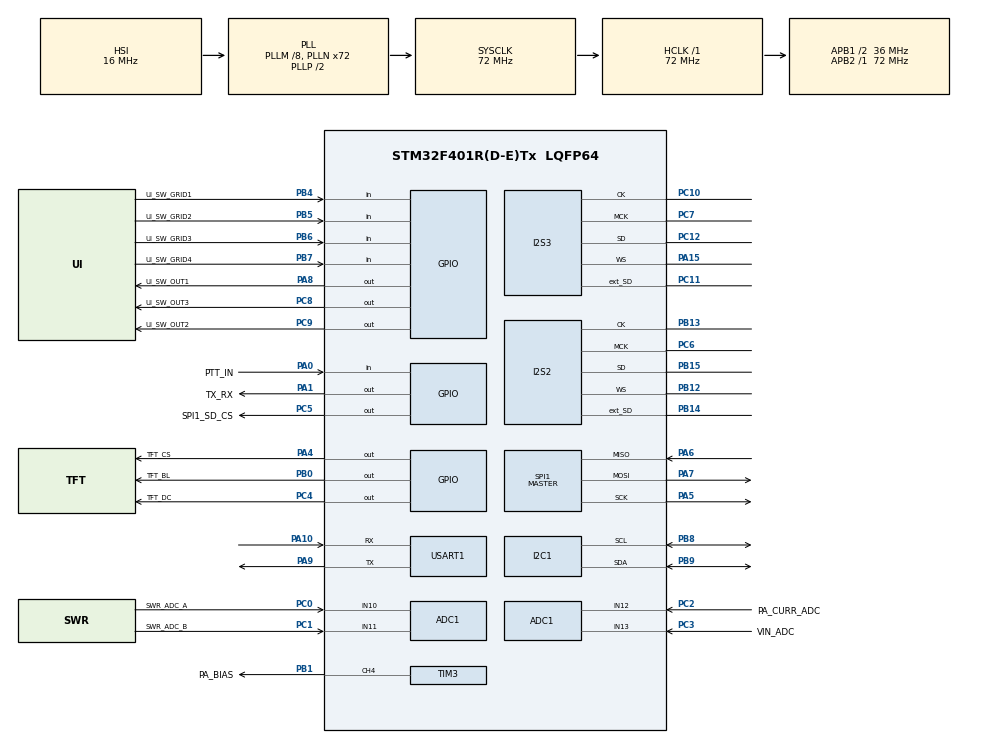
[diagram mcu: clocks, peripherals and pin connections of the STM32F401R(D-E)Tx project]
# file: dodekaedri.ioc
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ADC1.Channel-0\#ChannelRegularConversion=ADC_CHANNEL_13
ADC1.NbrOfConversionFlag=1
ADC1.Rank-0\#ChannelRegularConversion=1
ADC1.SamplingTime-0\#ChannelRegularConversion=ADC_SAMPLETIME_3CYCLES
ADC1.master=1
FREERTOS.Mutexes01=i2c_mutex
FREERTOS.Tasks01=defaultTask,0,128,StartDefaultTask,Default,NULL,Dynamic,NULL,NULL;ui_task,0,128,start_ui_task,As external,NULL,Dynamic,NULL,NULL;synth_task,0,128,start_synth_task,As external,NULL,Dynamic,NULL,NULL;dsp_task,1,128,start_dsp_task,As external,NULL,Dynamic,NULL,NULL
I2S2.AudioFreq=AudioFreqCustomValue
I2S2.AudioFreqCustom=50000
I2S2.ErrorAudioFreq=0.0 %
I2S2.FullDuplexMode=I2S_FULLDUPLEXMODE_ENABLE
I2S2.RealAudioFreq=50.0 KHz
I2S3.AudioFreq=AudioFreqCustomValue
I2S3.AudioFreqCustom=50000
I2S3.ErrorAudioFreq=0.0 %
I2S3.FullDuplexMode=I2S_FULLDUPLEXMODE_ENABLE
I2S3.RealAudioFreq=50.0 KHz
Mcu.Family=STM32F4
Mcu.Name=STM32F401R(D-E)Tx
Mcu.Package=LQFP64
NVIC.PriorityGroup=NVIC_PRIORITYGROUP_4
NVIC.SPI2_IRQn=true\:5\:0\:false\:false\:true\:true
PA0-WKUP.GPIO_Label=PTT_IN
PA0-WKUP.Signal=GPIO_Input
PA1.GPIO_Label=TX_RX
PA1.Signal=GPIO_Output
PA10.Mode=Asynchronous
PA10.Signal=USART1_RX
PA13.Signal=SYS_JTMS-SWDIO
PA14.Signal=SYS_JTCK-SWCLK
PA15.Mode=Full_Duplex_Master
PA15.Signal=I2S3_WS
PA4.GPIO_Label=TFT_CS
PA4.Signal=GPIO_Output
PA5.Mode=Full_Duplex_Master
PA5.Signal=SPI1_SCK
PA6.Mode=Full_Duplex_Master
PA6.Signal=SPI1_MISO
PA7.Mode=Full_Duplex_Master
PA7.Signal=SPI1_MOSI
PA8.GPIO_Label=UI_SW_OUT1
PA8.Signal=GPIO_Output
PA9.Mode=Asynchronous
PA9.Signal=USART1_TX
PB0.GPIO_Label=TFT_BL
PB0.Signal=GPIO_Output
PB1.GPIO_Label=PA_BIAS
PB1.Signal=S_TIM3_CH4
PB12.Mode=Full_Duplex_Master
PB12.Signal=I2S2_WS
PB13.Mode=Full_Duplex_Master
PB13.Signal=I2S2_CK
PB14.Mode=Full_Duplex_Master
PB14.Signal=I2S2_ext_SD
PB15.Mode=Full_Duplex_Master
PB15.Signal=I2S2_SD
PB3.Signal=SYS_JTDO-SWO
PB4.GPIO_Label=UI_SW_GRID1
PB4.Signal=GPIO_Input
PB5.GPIO_Label=UI_SW_GRID2
PB5.Signal=GPIO_Input
PB6.GPIO_Label=UI_SW_GRID3
PB6.Signal=GPIO_Input
PB7.GPIO_Label=UI_SW_GRID4
PB7.Signal=GPIO_Input
PB8.Mode=I2C
PB8.Signal=I2C1_SCL
PB9.Mode=I2C
PB9.Signal=I2C1_SDA
PC0.GPIO_Label=SWR_ADC_A
PC0.Signal=ADCx_IN10
PC1.GPIO_Label=SWR_ADC_B
PC1.Signal=ADCx_IN11
PC10.Mode=Full_Duplex_Master
PC10.Signal=I2S3_CK
PC11.Mode=Full_Duplex_Master
PC11.Signal=I2S3_ext_SD
PC12.Mode=Full_Duplex_Master
PC12.Signal=I2S3_SD
PC2.GPIO_Label=PA_CURR_ADC
PC2.Signal=ADCx_IN12
PC3.GPIO_Label=VIN_ADC
PC3.Signal=ADCx_IN13
PC4.GPIO_Label=TFT_DC
PC4.Signal=GPIO_Output
PC5.GPIO_Label=SPI1_SD_CS
PC5.Signal=GPIO_Output
PC6.Mode=Master_Clock_Activated
PC6.Signal=I2S2_MCK
PC7.Mode=Master_Clock_Activated
PC7.Signal=I2S3_MCK
PC8.GPIO_Label=UI_SW_OUT3
PC8.Signal=GPIO_Output
PC9.GPIO_Label=UI_SW_OUT2
PC9.Signal=GPIO_Output
PH0\ -\ OSC_IN.Mode=HSE-External-Clock-Source
PH0\ -\ OSC_IN.Signal=RCC_OSC_IN
PH1\ -\ OSC_OUT.Mode=HSE-External-Clock-Source
PH1\ -\ OSC_OUT.Signal=RCC_OSC_OUT
ProjectManager.HeapSize=0x200
ProjectManager.StackSize=0x400
ProjectManager.TargetToolchain=SW4STM32
RCC.48MHZClocksFreq_Value=48000000
RCC.AHBFreq_Value=72000000
RCC.APB1CLKDivider=RCC_HCLK_DIV2
RCC.APB1Freq_Value=36000000
RCC.APB1TimFreq_Value=72000000
RCC.APB2Freq_Value=72000000
RCC.APB2TimFreq_Value=72000000
RCC.CortexFreq_Value=72000000
RCC.HCLKFreq_Value=72000000
RCC.HSE_VALUE=25000000
RCC.HSI_VALUE=16000000
RCC.LSE_VALUE=32768
RCC.PLLM=8
RCC.PLLN=72
RCC.PLLQ=3
RCC.SYSCLKFreq_VALUE=72000000
RCC.SYSCLKSource=RCC_SYSCLKSOURCE_PLLCLK
RCC.VCOOutputFreq_Value=144000000
SH.ADCx_IN10.0=ADC1_IN10,IN10
SH.ADCx_IN11.0=ADC1_IN11,IN11
SH.ADCx_IN12.0=ADC1_IN12,IN12
SH.ADCx_IN13.0=ADC1_IN13,IN13
SH.S_TIM3_CH4.0=TIM3_CH4,PWM Generation4 CH4
SPI1.Mode=SPI_MODE_MASTER
TIM3.Channel-PWM\ Generation4\ CH4=TIM_CHANNEL_4
VP_FREERTOS_VS_ENABLE.Mode=Enabled
board=dodekaedri

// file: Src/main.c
/**
  ******************************************************************************
  * File Name          : main.c
  * Description        : Main program body
  ******************************************************************************
  *
  * Copyright (c) 2017 STMicroelectronics International N.V.
  * All rights reserved.
  *
  * Redistribution and use in source and binary forms, with or without
  * modification, are permitted, provided that the following conditions are met:
  *
  * 1. Redistribution of source code must retain the above copyright notice,
  *    this list of conditions and the following disclaimer.
  * 2. Redistributions in binary form must reproduce the above copyright notice,
  *    this list of conditions and the following disclaimer in the documentation
  *    and/or other materials provided with the distribution.
  * 3. Neither the name of STMicroelectronics nor the names of other
  *    contributors to this software may be used to endorse or promote products
  *    derived from this software without specific written permission.
  * 4. This software, including modifications and/or derivative works of this
  *    software, must execute solely and exclusively on microcontroller or
  *    microprocessor devices manufactured by or for STMicroelectronics.
  * 5. Redistribution and use of this software other than as permitted under
  *    this license is void and will automatically terminate your rights under
  *    this license.
  *
  * THIS SOFTWARE IS PROVIDED BY STMICROELECTRONICS AND CONTRIBUTORS "AS IS"
  * AND ANY EXPRESS, IMPLIED OR STATUTORY WARRANTIES, INCLUDING, BUT NOT
  * LIMITED TO, THE IMPLIED WARRANTIES OF MERCHANTABILITY, FITNESS FOR A
  * PARTICULAR PURPOSE AND NON-INFRINGEMENT OF THIRD PARTY INTELLECTUAL PROPERTY
  * RIGHTS ARE DISCLAIMED TO THE FULLEST EXTENT PERMITTED BY LAW. IN NO EVENT
  * SHALL STMICROELECTRONICS OR CONTRIBUTORS BE LIABLE FOR ANY DIRECT, INDIRECT,
  * INCIDENTAL, SPECIAL, EXEMPLARY, OR CONSEQUENTIAL DAMAGES (INCLUDING, BUT NOT
  * LIMITED TO, PROCUREMENT OF SUBSTITUTE GOODS OR SERVICES; LOSS OF USE, DATA,
  * OR PROFITS; OR BUSINESS INTERRUPTION) HOWEVER CAUSED AND ON ANY THEORY OF
  * LIABILITY, WHETHER IN CONTRACT, STRICT LIABILITY, OR TORT (INCLUDING
  * NEGLIGENCE OR OTHERWISE) ARISING IN ANY WAY OUT OF THE USE OF THIS SOFTWARE,
  * EVEN IF ADVISED OF THE POSSIBILITY OF SUCH DAMAGE.
  *
  ******************************************************************************
  */
#include "main.h"
#include "stm32f4xx_hal.h"
#include "cmsis_os.h"

ADC_HandleTypeDef hadc1;

I2C_HandleTypeDef hi2c1;

I2S_HandleTypeDef hi2s2;
I2S_HandleTypeDef hi2s3;

SPI_HandleTypeDef hspi1;

TIM_HandleTypeDef htim3;

UART_HandleTypeDef huart1;

osThreadId defaultTaskHandle;
osThreadId ui_taskHandle;
osThreadId synth_taskHandle;
osThreadId dsp_taskHandle;
osMutexId i2c_mutexHandle;

/* USER CODE BEGIN PV */
/* Private variables ---------------------------------------------------------*/

/* USER CODE END PV */

void SystemClock_Config(void);
void Error_Handler(void);
static void MX_GPIO_Init(void);
static void MX_ADC1_Init(void);
static void MX_SPI1_Init(void);
static void MX_TIM3_Init(void);
static void MX_I2S2_Init(void);
static void MX_I2S3_Init(void);
static void MX_I2C1_Init(void);
static void MX_USART1_UART_Init(void);
void StartDefaultTask(void const * argument);
extern void start_ui_task(void const * argument);
extern void start_synth_task(void const * argument);
extern void start_dsp_task(void const * argument);

void HAL_TIM_MspPostInit(TIM_HandleTypeDef *htim);

/* USER CODE BEGIN PFP */
/* Private function prototypes -----------------------------------------------*/

/* USER CODE END PFP */

int main(void)
{

  /* MCU Configuration----------------------------------------------------------*/

  /* Reset of all peripherals, Initializes the Flash interface and the Systick. */
  HAL_Init();

  /* Configure the system clock */
  SystemClock_Config();

  /* Initialize all configured peripherals */
  MX_GPIO_Init();
  MX_ADC1_Init();
  MX_SPI1_Init();
  MX_TIM3_Init();
  MX_I2S2_Init();
  MX_I2S3_Init();
  MX_I2C1_Init();
  MX_USART1_UART_Init();

  /* USER CODE BEGIN 2 */
  HAL_UART_Transmit(&huart1, "MCU peripherals initialized. Starting kernel\r\n", 47, 100);

  /* USER CODE END 2 */

  /* Create the mutex(es) */
  /* definition and creation of i2c_mutex */
  osMutexDef(i2c_mutex);
  i2c_mutexHandle = osMutexCreate(osMutex(i2c_mutex));

  /* Create the thread(s) */
  /* definition and creation of defaultTask */
  osThreadDef(defaultTask, StartDefaultTask, osPriorityNormal, 0, 128);
  defaultTaskHandle = osThreadCreate(osThread(defaultTask), NULL);

  /* definition and creation of ui_task */
  osThreadDef(ui_task, start_ui_task, osPriorityNormal, 0, 128);
  ui_taskHandle = osThreadCreate(osThread(ui_task), NULL);

  /* definition and creation of synth_task */
  osThreadDef(synth_task, start_synth_task, osPriorityNormal, 0, 128);
  synth_taskHandle = osThreadCreate(osThread(synth_task), NULL);

  /* definition and creation of dsp_task */
  osThreadDef(dsp_task, start_dsp_task, osPriorityAboveNormal, 0, 128);
  dsp_taskHandle = osThreadCreate(osThread(dsp_task), NULL);

  /* Start scheduler */
  osKernelStart();

  /* We should never get here as control is now taken by the scheduler */

  /* Infinite loop */
  while (1)
  {

  }

}

/** System Clock Configuration
*/
void SystemClock_Config(void)
{

  RCC_OscInitTypeDef RCC_OscInitStruct;
  RCC_ClkInitTypeDef RCC_ClkInitStruct;
  RCC_PeriphCLKInitTypeDef PeriphClkInitStruct;

    /**Configure the main internal regulator output voltage
    */
  __HAL_RCC_PWR_CLK_ENABLE();

  __HAL_PWR_VOLTAGESCALING_CONFIG(PWR_REGULATOR_VOLTAGE_SCALE2);

    /**Initializes the CPU, AHB and APB busses clocks
    */
  RCC_OscInitStruct.OscillatorType = RCC_OSCILLATORTYPE_HSI;
  RCC_OscInitStruct.HSIState = RCC_HSI_ON;
  RCC_OscInitStruct.HSICalibrationValue = 16;
  RCC_OscInitStruct.PLL.PLLState = RCC_PLL_ON;
  RCC_OscInitStruct.PLL.PLLSource = RCC_PLLSOURCE_HSI;
  RCC_OscInitStruct.PLL.PLLM = 8;
  RCC_OscInitStruct.PLL.PLLN = 72;
  RCC_OscInitStruct.PLL.PLLP = RCC_PLLP_DIV2;
  RCC_OscInitStruct.PLL.PLLQ = 3;
  if (HAL_RCC_OscConfig(&RCC_OscInitStruct) != HAL_OK)
  {
    Error_Handler();
  }

    /**Initializes the CPU, AHB and APB busses clocks
    */
  RCC_ClkInitStruct.ClockType = RCC_CLOCKTYPE_HCLK|RCC_CLOCKTYPE_SYSCLK
                              |RCC_CLOCKTYPE_PCLK1|RCC_CLOCKTYPE_PCLK2;
  RCC_ClkInitStruct.SYSCLKSource = RCC_SYSCLKSOURCE_PLLCLK;
  RCC_ClkInitStruct.AHBCLKDivider = RCC_SYSCLK_DIV1;
  RCC_ClkInitStruct.APB1CLKDivider = RCC_HCLK_DIV2;
  RCC_ClkInitStruct.APB2CLKDivider = RCC_HCLK_DIV1;

  if (HAL_RCC_ClockConfig(&RCC_ClkInitStruct, FLASH_LATENCY_2) != HAL_OK)
  {
    Error_Handler();
  }

  PeriphClkInitStruct.PeriphClockSelection = RCC_PERIPHCLK_I2S;
  PeriphClkInitStruct.PLLI2S.PLLI2SN = 192;
  PeriphClkInitStruct.PLLI2S.PLLI2SR = 2;
  if (HAL_RCCEx_PeriphCLKConfig(&PeriphClkInitStruct) != HAL_OK)
  {
    Error_Handler();
  }

    /**Configure the Systick interrupt time
    */
  HAL_SYSTICK_Config(HAL_RCC_GetHCLKFreq()/1000);

    /**Configure the Systick
    */
  HAL_SYSTICK_CLKSourceConfig(SYSTICK_CLKSOURCE_HCLK);

  /* SysTick_IRQn interrupt configuration */
  HAL_NVIC_SetPriority(SysTick_IRQn, 15, 0);
}

/* ADC1 init function */
static void MX_ADC1_Init(void)
{

  ADC_ChannelConfTypeDef sConfig;

    /**Configure the global features of the ADC (Clock, Resolution, Data Alignment and number of conversion)
    */
  hadc1.Instance = ADC1;
  hadc1.Init.ClockPrescaler = ADC_CLOCK_SYNC_PCLK_DIV2;
  hadc1.Init.Resolution = ADC_RESOLUTION_12B;
  hadc1.Init.ScanConvMode = DISABLE;
  hadc1.Init.ContinuousConvMode = DISABLE;
  hadc1.Init.DiscontinuousConvMode = DISABLE;
  hadc1.Init.ExternalTrigConvEdge = ADC_EXTERNALTRIGCONVEDGE_NONE;
  hadc1.Init.ExternalTrigConv = ADC_SOFTWARE_START;
  hadc1.Init.DataAlign = ADC_DATAALIGN_RIGHT;
  hadc1.Init.NbrOfConversion = 1;
  hadc1.Init.DMAContinuousRequests = DISABLE;
  hadc1.Init.EOCSelection = ADC_EOC_SINGLE_CONV;
  if (HAL_ADC_Init(&hadc1) != HAL_OK)
  {
    Error_Handler();
  }

    /**Configure for the selected ADC regular channel its corresponding rank in the sequencer and its sample time.
    */
  sConfig.Channel = ADC_CHANNEL_13;
  sConfig.Rank = 1;
  sConfig.SamplingTime = ADC_SAMPLETIME_3CYCLES;
  if (HAL_ADC_ConfigChannel(&hadc1, &sConfig) != HAL_OK)
  {
    Error_Handler();
  }

}

/* I2C1 init function */
static void MX_I2C1_Init(void)
{

  hi2c1.Instance = I2C1;
  hi2c1.Init.ClockSpeed = 100000;
  hi2c1.Init.DutyCycle = I2C_DUTYCYCLE_2;
  hi2c1.Init.OwnAddress1 = 0;
  hi2c1.Init.AddressingMode = I2C_ADDRESSINGMODE_7BIT;
  hi2c1.Init.DualAddressMode = I2C_DUALADDRESS_DISABLE;
  hi2c1.Init.OwnAddress2 = 0;
  hi2c1.Init.GeneralCallMode = I2C_GENERALCALL_DISABLE;
  hi2c1.Init.NoStretchMode = I2C_NOSTRETCH_DISABLE;
  if (HAL_I2C_Init(&hi2c1) != HAL_OK)
  {
    Error_Handler();
  }

}

/* I2S2 init function */
static void MX_I2S2_Init(void)
{

  hi2s2.Instance = SPI2;
  hi2s2.Init.Mode = I2S_MODE_MASTER_TX;
  hi2s2.Init.Standard = I2S_STANDARD_PHILIPS;
  hi2s2.Init.DataFormat = I2S_DATAFORMAT_16B;
  hi2s2.Init.MCLKOutput = I2S_MCLKOUTPUT_ENABLE;
  hi2s2.Init.AudioFreq = 50000;
  hi2s2.Init.CPOL = I2S_CPOL_LOW;
  hi2s2.Init.ClockSource = I2S_CLOCK_PLL;
  hi2s2.Init.FullDuplexMode = I2S_FULLDUPLEXMODE_ENABLE;
  if (HAL_I2S_Init(&hi2s2) != HAL_OK)
  {
    Error_Handler();
  }

}

/* I2S3 init function */
static void MX_I2S3_Init(void)
{

  hi2s3.Instance = SPI3;
  hi2s3.Init.Mode = I2S_MODE_MASTER_TX;
  hi2s3.Init.Standard = I2S_STANDARD_PHILIPS;
  hi2s3.Init.DataFormat = I2S_DATAFORMAT_16B;
  hi2s3.Init.MCLKOutput = I2S_MCLKOUTPUT_ENABLE;
  hi2s3.Init.AudioFreq = 50000;
  hi2s3.Init.CPOL = I2S_CPOL_LOW;
  hi2s3.Init.ClockSource = I2S_CLOCK_PLL;
  hi2s3.Init.FullDuplexMode = I2S_FULLDUPLEXMODE_ENABLE;
  if (HAL_I2S_Init(&hi2s3) != HAL_OK)
  {
    Error_Handler();
  }

}

/* SPI1 init function */
static void MX_SPI1_Init(void)
{

  hspi1.Instance = SPI1;
  hspi1.Init.Mode = SPI_MODE_MASTER;
  hspi1.Init.Direction = SPI_DIRECTION_2LINES;
  hspi1.Init.DataSize = SPI_DATASIZE_8BIT;
  hspi1.Init.CLKPolarity = SPI_POLARITY_LOW;
  hspi1.Init.CLKPhase = SPI_PHASE_1EDGE;
  hspi1.Init.NSS = SPI_NSS_SOFT;
  hspi1.Init.BaudRatePrescaler = SPI_BAUDRATEPRESCALER_2;
  hspi1.Init.FirstBit = SPI_FIRSTBIT_MSB;
  hspi1.Init.TIMode = SPI_TIMODE_DISABLE;
  hspi1.Init.CRCCalculation = SPI_CRCCALCULATION_DISABLE;
  hspi1.Init.CRCPolynomial = 10;
  if (HAL_SPI_Init(&hspi1) != HAL_OK)
  {
    Error_Handler();
  }

}

/* TIM3 init function */
static void MX_TIM3_Init(void)
{

  TIM_MasterConfigTypeDef sMasterConfig;
  TIM_OC_InitTypeDef sConfigOC;

  htim3.Instance = TIM3;
  htim3.Init.Prescaler = 0;
  htim3.Init.CounterMode = TIM_COUNTERMODE_UP;
  htim3.Init.Period = 0;
  htim3.Init.ClockDivision = TIM_CLOCKDIVISION_DIV1;
  if (HAL_TIM_PWM_Init(&htim3) != HAL_OK)
  {
    Error_Handler();
  }

  sMasterConfig.MasterOutputTrigger = TIM_TRGO_RESET;
  sMasterConfig.MasterSlaveMode = TIM_MASTERSLAVEMODE_DISABLE;
  if (HAL_TIMEx_MasterConfigSynchronization(&htim3, &sMasterConfig) != HAL_OK)
  {
    Error_Handler();
  }

  sConfigOC.OCMode = TIM_OCMODE_PWM1;
  sConfigOC.Pulse = 0;
  sConfigOC.OCPolarity = TIM_OCPOLARITY_HIGH;
  sConfigOC.OCFastMode = TIM_OCFAST_DISABLE;
  if (HAL_TIM_PWM_ConfigChannel(&htim3, &sConfigOC, TIM_CHANNEL_4) != HAL_OK)
  {
    Error_Handler();
  }

  HAL_TIM_MspPostInit(&htim3);

}

/* USART1 init function */
static void MX_USART1_UART_Init(void)
{

  huart1.Instance = USART1;
  huart1.Init.BaudRate = 115200;
  huart1.Init.WordLength = UART_WORDLENGTH_8B;
  huart1.Init.StopBits = UART_STOPBITS_1;
  huart1.Init.Parity = UART_PARITY_NONE;
  huart1.Init.Mode = UART_MODE_TX_RX;
  huart1.Init.HwFlowCtl = UART_HWCONTROL_NONE;
  huart1.Init.OverSampling = UART_OVERSAMPLING_16;
  if (HAL_UART_Init(&huart1) != HAL_OK)
  {
    Error_Handler();
  }

}

/** Configure pins as
        * Analog
        * Input
        * Output
        * EVENT_OUT
        * EXTI
*/
static void MX_GPIO_Init(void)
{

  GPIO_InitTypeDef GPIO_InitStruct;

  /* GPIO Ports Clock Enable */
  __HAL_RCC_GPIOH_CLK_ENABLE();
  __HAL_RCC_GPIOC_CLK_ENABLE();
  __HAL_RCC_GPIOA_CLK_ENABLE();
  __HAL_RCC_GPIOB_CLK_ENABLE();

  /*Configure GPIO pin Output Level */
  HAL_GPIO_WritePin(GPIOA, TX_RX_Pin|TFT_CS_Pin|UI_SW_OUT1_Pin, GPIO_PIN_RESET);

  /*Configure GPIO pin Output Level */
  HAL_GPIO_WritePin(GPIOC, TFT_DC_Pin|SPI1_SD_CS_Pin|UI_SW_OUT3_Pin|UI_SW_OUT2_Pin, GPIO_PIN_RESET);

  /*Configure GPIO pin Output Level */
  HAL_GPIO_WritePin(TFT_BL_GPIO_Port, TFT_BL_Pin, GPIO_PIN_RESET);

  /*Configure GPIO pin : PTT_IN_Pin */
  GPIO_InitStruct.Pin = PTT_IN_Pin;
  GPIO_InitStruct.Mode = GPIO_MODE_INPUT;
  GPIO_InitStruct.Pull = GPIO_NOPULL;
  HAL_GPIO_Init(PTT_IN_GPIO_Port, &GPIO_InitStruct);

  /*Configure GPIO pins : TX_RX_Pin TFT_CS_Pin UI_SW_OUT1_Pin */
  GPIO_InitStruct.Pin = TX_RX_Pin|TFT_CS_Pin|UI_SW_OUT1_Pin;
  GPIO_InitStruct.Mode = GPIO_MODE_OUTPUT_PP;
  GPIO_InitStruct.Pull = GPIO_NOPULL;
  GPIO_InitStruct.Speed = GPIO_SPEED_FREQ_LOW;
  HAL_GPIO_Init(GPIOA, &GPIO_InitStruct);

  /*Configure GPIO pins : TFT_DC_Pin SPI1_SD_CS_Pin UI_SW_OUT3_Pin UI_SW_OUT2_Pin */
  GPIO_InitStruct.Pin = TFT_DC_Pin|SPI1_SD_CS_Pin|UI_SW_OUT3_Pin|UI_SW_OUT2_Pin;
  GPIO_InitStruct.Mode = GPIO_MODE_OUTPUT_PP;
  GPIO_InitStruct.Pull = GPIO_NOPULL;
  GPIO_InitStruct.Speed = GPIO_SPEED_FREQ_LOW;
  HAL_GPIO_Init(GPIOC, &GPIO_InitStruct);

  /*Configure GPIO pin : TFT_BL_Pin */
  GPIO_InitStruct.Pin = TFT_BL_Pin;
  GPIO_InitStruct.Mode = GPIO_MODE_OUTPUT_PP;
  GPIO_InitStruct.Pull = GPIO_NOPULL;
  GPIO_InitStruct.Speed = GPIO_SPEED_FREQ_LOW;
  HAL_GPIO_Init(TFT_BL_GPIO_Port, &GPIO_InitStruct);

  /*Configure GPIO pins : UI_SW_GRID1_Pin UI_SW_GRID2_Pin UI_SW_GRID3_Pin UI_SW_GRID4_Pin */
  GPIO_InitStruct.Pin = UI_SW_GRID1_Pin|UI_SW_GRID2_Pin|UI_SW_GRID3_Pin|UI_SW_GRID4_Pin;
  GPIO_InitStruct.Mode = GPIO_MODE_INPUT;
  GPIO_InitStruct.Pull = GPIO_NOPULL;
  HAL_GPIO_Init(GPIOB, &GPIO_InitStruct);

}

/* StartDefaultTask function */
void StartDefaultTask(void const * argument)
{

  for(;;)
  {
    osDelay(1);
  }
}

void Error_Handler(void)
{
  while(1)
  {
  }
}

/************************ (C) COPYRIGHT STMicroelectronics *****END OF FILE****/
